# wl_phy_ana_pg_secure register map
Vendor: Texas Instruments
Peripheral module from a debugger description file (folder CC35X1E).
Registers are 32-bit, access per field, reset 0x0 unless marked. A register's access mark holds for its fields unless they carry their own. Offsets are as the file gives them; lines under a group give offsets from that group; [hi:lo] are bit positions; {n}, {i} and the like mark numbered series; 'fields as' and 'values as' point back to an identical list; <NAME> marks a mode.

## wl_phy_ana_pg_secure (part 1 of 3)
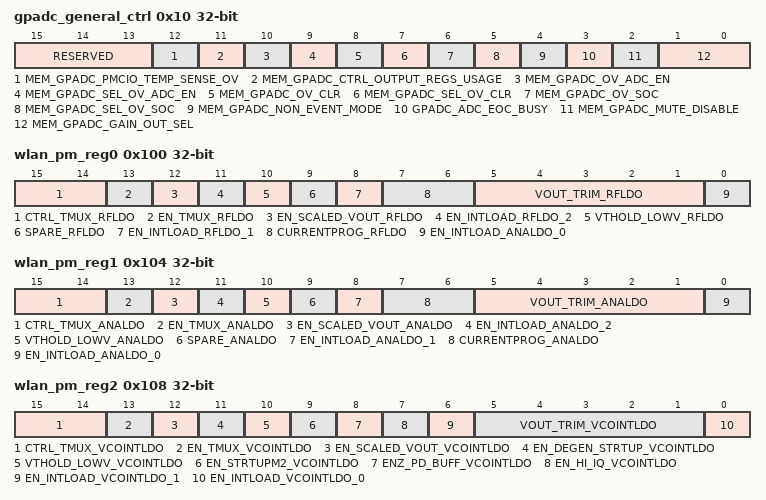
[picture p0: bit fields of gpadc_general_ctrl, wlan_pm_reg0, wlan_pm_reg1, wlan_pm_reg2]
0x10 gpadc_general_ctrl
  [15:13] RESERVED rw, [12] MEM_GPADC_PMCIO_TEMP_SENSE_OV rw, [11] MEM_GPADC_CTRL_OUTPUT_REGS_USAGE rw, [10] MEM_GPADC_OV_ADC_EN rw, [9] MEM_GPADC_SEL_OV_ADC_EN rw, [8] MEM_GPADC_OV_CLR rw, [7] MEM_GPADC_SEL_OV_CLR rw, [6] MEM_GPADC_OV_SOC rw, [5] MEM_GPADC_SEL_OV_SOC rw, [4] MEM_GPADC_NON_EVENT_MODE rw, [3] GPADC_ADC_EOC_BUSY rw, [2] MEM_GPADC_MUTE_DISABLE rw, [1:0] MEM_GPADC_GAIN_OUT_SEL rw
0x70 pmcio_regs
  [15:0] MEM_GPADC_REG0 rw
0x100 wlan_pm_reg0 — Trim bit to control internal load current (EN_INTLOAD)
  [15:14] CTRL_TMUX_RFLDO rw — CTRL_TMUX_1P8V 0_0 _ Bring out VDDA through TMUX 0_1 _ Bring out 2*Iref through TMUX 1_0_ Bring out Vout through TMUX 1_1_ Bring out VSSA through TMUX
  [13] EN_TMUX_RFLDO rw — Enable TMUX _H_ = Enable TMUX block_ _L_ = Disable
  [12] EN_SCALED_VOUT_RFLDO rw — Bring out scaled Vout (Vout_2) _H_ = Enable Vout scale block_ _L_ = Disable
  [11] EN_INTLOAD_RFLDO_2 rw — Trim bit to control internal load current (EN_INTLOAD)
  [10] VTHOLD_LOWV_RFLDO rw — VTHOLD bit of RFLDO30MA_2
  [9] SPARE_RFLDO rw — Spare bit
  [8] EN_INTLOAD_RFLDO_1 rw — Trim bit to control internal load current (EN_INTLOAD)
  [7:6] CURRENTPROG_RFLDO rw — CURRENTPROG Enable extra 80uA current in buffer (CURRENTPROG) Enable extra 40uA current in buffer (CURRENTPROG)
  [5:1] VOUT_TRIM_RFLDO rw — LDO output voltage trim_ VOUT_TRIM LSB = 20mV. For 1.3V output_ trim = 19
  [0] EN_INTLOAD_ANALDO_0 rw — Trim bit to control internal load current (EN_INTLOAD)
0x104 wlan_pm_reg1 — Trim bit to control internal load current (EN_INTLOAD)
  [15:14] CTRL_TMUX_ANALDO rw — CTRL_TMUX_1P8V 0_0 _ Bring out VDDA through TMUX 0_1 _ Bring out 2*Iref through TMUX 1_0_ Bring out Vout through TMUX 1_1_ Bring out VSSA through TMUX
  [13] EN_TMUX_ANALDO rw — Enable TMUX _H_ = Enable TMUX block_ _L_ = Disable
  [12] EN_SCALED_VOUT_ANALDO rw — Bring out scaled Vout (Vout_2) _H_ = Enable Vout scale block_ _L_ = Disable
  [11] EN_INTLOAD_ANALDO_2 rw — Trim bit to control internal load current (EN_INTLOAD)
  [10] VTHOLD_LOWV_ANALDO rw — VTHOLD bit of RFLDO30MA_1
  [9] SPARE_ANALDO rw — Spare bit
  [8] EN_INTLOAD_ANALDO_1 rw — Trim bit to control internal load current (EN_INTLOAD)
  [7:6] CURRENTPROG_ANALDO rw — CURRENTPROG Enable extra 80uA current in buffer (CURRENTPROG) Enable extra 40uA current in buffer (CURRENTPROG)
  [5:1] VOUT_TRIM_ANALDO rw — LDO output voltage trim_ VOUT_TRIM LSB = 20mV. For 1.3V output_ trim = 19
  [0] EN_INTLOAD_ANALDO_0 rw — Trim bit to control internal load current (EN_INTLOAD)
0x108 wlan_pm_reg2 — Trim bit to control internal load current (EN_INTLOAD)
  [15:14] CTRL_TMUX_VCOINTLDO rw — CTRL_TMUX_1P8V 0_0 _ Bring out VDDA through TMUX 0_1 _ Bring out 2*Iref through TMUX 1_0_ Bring out Vout through TMUX 1_1_ Bring out VSSA through TMUX
  [13] EN_TMUX_VCOINTLDO rw — Enable TMUX _H_ = Enable TMUX block_ _L_ = Disable
  [12] EN_SCALED_VOUT_VCOINTLDO rw — Bring out scaled Vout (Vout_2) _H_ = Enable Vout scale block_ _L_ = Disable
  [11] EN_DEGEN_STRTUP_VCOINTLDO rw — Start-up amp's degeneration _L_ = short out degen_ _H_ = keep degen
  [10] VTHOLD_LOWV_VCOINTLDO rw — VTHOLD_LOWV of VCOINTLDO
  [9] EN_STRTUPM2_VCOINTLDO rw — Burn extra current in EA for faster start-up _L_ = only 2.5uA extra_ _H_ = 10uA extra
  [8] ENZ_PD_BUFF_VCOINTLDO rw — Enable PMOS pull down path in buffer _L_ = Enable PD_ _H_ = Disable PD
  [7] EN_HI_IQ_VCOINTLDO rw — Enable high quiescent current mode
  [6] EN_INTLOAD_VCOINTLDO_1 rw — Trim bit to control internal load current (EN_INTLOAD)
  [5:1] VOUT_TRIM_VCOINTLDO rw — LDO output voltage trim_ VOUT_TRIM LSB = 20mV. For 1.3V output_ trim = 19
  [0] EN_INTLOAD_VCOINTLDO_0 rw — Trim bit to control internal load current (EN_INTLOAD)
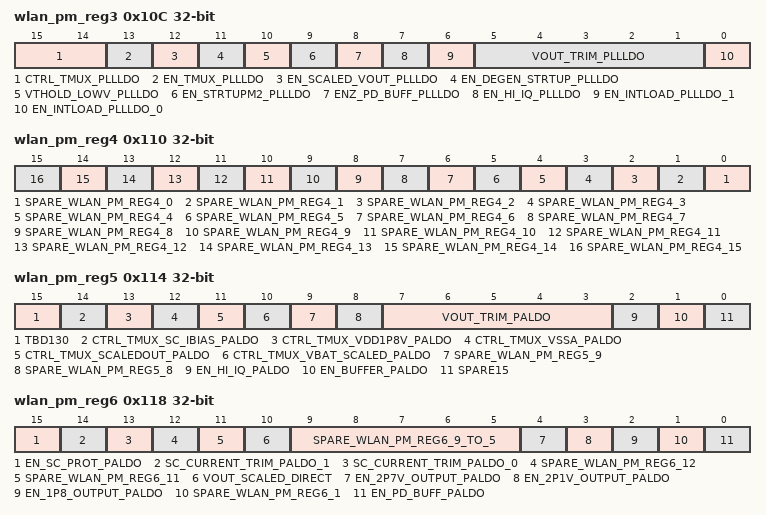
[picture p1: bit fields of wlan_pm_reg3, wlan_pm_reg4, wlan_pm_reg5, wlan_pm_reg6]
0x10C wlan_pm_reg3 — Trim bit to control internal load current (EN_INTLOAD)
  [15:14] CTRL_TMUX_PLLLDO rw — CTRL_TMUX_1P8V 0_0 _ Bring out VDDA through TMUX 0_1 _ Bring out 2*Iref through TMUX 1_0_ Bring out Vout through TMUX 1_1_ Bring out VSSA through TMUX
  [13] EN_TMUX_PLLLDO rw — Enable TMUX _H_ = Enable TMUX block_ _L_ = Disable
  [12] EN_SCALED_VOUT_PLLLDO rw — Bring out scaled Vout (Vout_2) _H_ = Enable Vout scale block_ _L_ = Disable
  [11] EN_DEGEN_STRTUP_PLLLDO rw — Start-up amp's degeneration _L_ = short out degen_ _H_ = keep degen
  [10] VTHOLD_LOWV_PLLLDO rw — VTHOLD_LOWV of PLLLDO
  [9] EN_STRTUPM2_PLLLDO rw — Burn extra current in EA for faster start-up _L_ = only 2.5uA extra_ _H_ = 10uA extra (EN_STARTUPMODE_2)
  [8] ENZ_PD_BUFF_PLLLDO rw — Enable PMOS pull down path in buffer _L_ = Enable PD_ _H_ = Disable PD
  [7] EN_HI_IQ_PLLLDO rw — Enable high quiescent current mode
  [6] EN_INTLOAD_PLLLDO_1 rw — Trim bit to control internal load current (EN_INTLOAD)
  [5:1] VOUT_TRIM_PLLLDO rw — LDO output voltage trim_ VOUT_TRIM LSB = 20mV. For 1.3V output_ trim = 19
  [0] EN_INTLOAD_PLLLDO_0 rw — Trim bit to control internal load current (EN_INTLOAD)
0x110 wlan_pm_reg4 — Spare bit
  [n] SPARE_WLAN_PM_REG4_{n} rw (n=0..15) — Spare bit
0x114 wlan_pm_reg5 — SPARE bit
  [15] TBD130 rw — Unused
  [14] CTRL_TMUX_SC_IBIAS_PALDO rw — Bring out _SC_BIAS_CURRENT_ This will be used for current trimming
  [13] CTRL_TMUX_VDD1P8V_PALDO rw — Bring out _VDD_1P8V_
  [12] CTRL_TMUX_VSSA_PALDO rw — Bring out _VSSA_
  [11] CTRL_TMUX_SCALEDOUT_PALDO rw — Bring out _OUT_SCALED_1P2V_
  [10] CTRL_TMUX_VBAT_SCALED_PALDO rw — Bring out VBAT_SCALED through test-mux Scaling factor = (approx) 0.175 SPARE_REG2 also need to be set to _H_H_ _L_ = Disable_ _H_ = Enable this path in TMUX
  [9] SPARE_WLAN_PM_REG5_9 rw — Spare bit
  [8] SPARE_WLAN_PM_REG5_8 rw — Spare bit
  [7:3] VOUT_TRIM_PALDO rw — LDO output voltage trim_ VOUT_TRIM Bit VOUT_TRIM is unused
  [2] EN_HI_IQ_PALDO rw — Enable high quiescent current mode (HI_IQ_EN) _L_ = Low quiescent current_ _H_ = High quiescent current
  [1] EN_BUFFER_PALDO rw — Enable Buffer (fast loop) of LDO (EN_VBAT_SUPPLY_LOWV) _L_ = Disable_ _H_ = Enable
  [0] SPARE15 rw — SPARE bit
0x118 wlan_pm_reg6 — Enable buffer pull down path (ACTIVE_NMOS_PD_EN) _L_ = Enable pull down_ _H_ = Disable pull down
  [15] EN_SC_PROT_PALDO rw — Enable SC_PROT block _L_ = Disable SC_PROT_ _H_ = Enable SC_PROT
  [14] SC_CURRENT_TRIM_PALDO_1 rw — Unused
  [13] SC_CURRENT_TRIM_PALDO_0 rw — Change the bias current of SC_PROT block _L_ = 5uA current_ _H_ = 10uA current
  [12] SPARE_WLAN_PM_REG6_12 rw — SPARE bit
  [11] SPARE_WLAN_PM_REG6_11 rw — SPARE bit
  [10] VOUT_SCALED_DIRECT rw — Bring out VOUT_SCALED directly through OUT_1P2V pin [Scaling factor (approx.) = 2_9 ] _L_ = Disable_ _H_ = Enable the path to bring out the above mentioned signal (internally called TEST_EN)
  [9:5] SPARE_WLAN_PM_REG6_9_TO_5 rw — SPARE bit
  [4] EN_2P7V_OUTPUT_PALDO rw — Enable High output voltage mode(2.49 - 2.95V) [EN_HIPWR_MODE] _L_ = Operate 2.4V max output_ _H_ = operate at 2.7V max output
  [3] EN_2P1V_OUTPUT_PALDO rw — Enable 1.93V to 2.31V output mode (EN_1P8_SUPPLY_LOWV) H = operate in 1.93V-2.31V output range_ L = operate at higher output Also see SPARE_REG2
  [2] EN_1P8_OUTPUT_PALDO rw — Enable lowest trim range (1.65V - 1.95V) _L_ = Don't enable lowest output mode_ _H_ = Enable lowest trim range_ and override the other two bits
  [1] SPARE_WLAN_PM_REG6_1 rw — SPARE bit
  [0] EN_PD_BUFF_PALDO rw — Enable buffer pull down path (ACTIVE_NMOS_PD_EN) _L_ = Enable pull down_ _H_ = Disable pull down
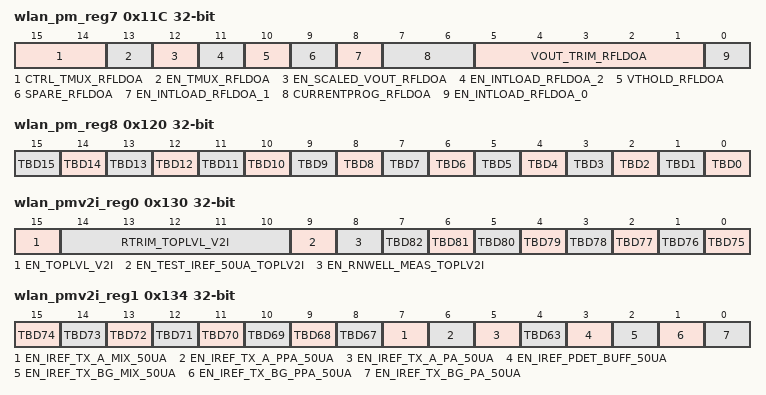
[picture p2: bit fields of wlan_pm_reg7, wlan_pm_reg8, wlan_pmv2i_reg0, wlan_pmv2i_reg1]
0x11C wlan_pm_reg7 — Trim bit to control internal load current (EN_INTLOAD)
  [15:14] CTRL_TMUX_RFLDOA rw — CTRL_TMUX_1P8V 0_0 _ Bring out VDDA through TMUX 0_1 _ Bring out 2*Iref through TMUX 1_0_ Bring out Vout through TMUX 1_1_ Bring out VSSA through TMUX
  [13] EN_TMUX_RFLDOA rw — Enable TMUX _H_ = Enable TMUX block_ _L_ = Disable
  [12] EN_SCALED_VOUT_RFLDOA rw — Bring out scaled Vout (Vout_2) _H_ = Enable Vout scale block_ _L_ = Disable
  [11] EN_INTLOAD_RFLDOA_2 rw — Trim bit to control internal load current (EN_INTLOAD)
  [10] VTHOLD_RFLDOA rw — VTHOLD_LOWV bit for RFLDO60MA
  [9] SPARE_RFLDOA rw — Spare bit
  [8] EN_INTLOAD_RFLDOA_1 rw — Trim bit to control internal load current (EN_INTLOAD)
  [7:6] CURRENTPROG_RFLDOA rw — CURRENTPROG Enable extra 80uA current in buffer (CURRENTPROG) Enable extra 40uA current in buffer (CURRENTPROG)
  [5:1] VOUT_TRIM_RFLDOA rw — LDO output voltage trim_ VOUT_TRIM LSB = 20mV. For 1.3V output_ trim = 19
  [0] EN_INTLOAD_RFLDOA_0 rw — Trim bit to control internal load current (EN_INTLOAD)
0x120 wlan_pm_reg8
  [n] TBD{n} rw (n=0..15)
0x124 wlan_pm_reg9 reset 0x1B001B — MEM_WLAN_PM_REG9
  [15:0] WLAN_PM_REG9_15_0 rw
0x130 wlan_pmv2i_reg0
  [15] EN_TOPLVL_V2I rw — Global enable of V2I _L_ = Disable_ _H_ = Enable V2I module
  [14:10] RTRIM_TOPLVL_V2I rw — RTRIM Nom_27 = 0_1_1_1_1 (15) Nom_-40 = 0_1_1_1_1 (15) Nom_125 = 0_1_0_1_0 (10) Strong_27 = 1_1_1_0_1 (29) Strong_-40 = 1_1_1_1_0 (30) Strong_125 = 1_1_0_1_1 (27) Weak_27 = 0_0_1_0_1 (5) Weak_-40 = 0_0_1_0_1 (5) Weak_125 = 0_0_0_0_0 (0)
  [9] EN_TEST_IREF_50UA_TOPLV2I rw — EN_TEST_IREF_50UA _L_ = Disable_ _H_ = Bring out 50uA test current
  [8] EN_RNWELL_MEAS_TOPLV2I rw — Enable 9.70kOhm resistor for RNWELL measurement
  [n-75] TBD{n} rw (n=75..82)
0x134 wlan_pmv2i_reg1 — IREF_PA_50UA
  [n-59] TBD{n} rw (n=68..74)
  [8] TBD67 rw — TBD (A-band)
  [7] EN_IREF_TX_A_MIX_50UA rw — IREF_MIX_50UA (A)
  [6] EN_IREF_TX_A_PPA_50UA rw — IREF_PPA_50UA (A)
  [5] EN_IREF_TX_A_PA_50UA rw — IREF_PA_50UA (A)
  [4] TBD63 rw
  [3] EN_IREF_PDET_BUFF_50UA rw — PDET_BUF (IREF_50UA)
  [2] EN_IREF_TX_BG_MIX_50UA rw — IREF_MIX_50UA
  [1] EN_IREF_TX_BG_PPA_50UA rw — IREF_PPA_50UA
  [0] EN_IREF_TX_BG_PA_50UA rw — IREF_PA_50UA
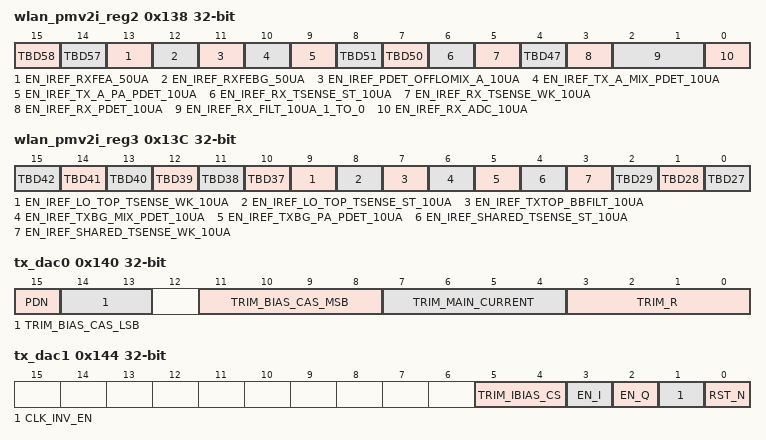
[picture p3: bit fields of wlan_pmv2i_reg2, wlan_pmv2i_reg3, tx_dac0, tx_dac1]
0x138 wlan_pmv2i_reg2 — IREF_ADC_10UA (WLAN_RX_TOP)
  [15] TBD58 rw
  [14] TBD57 rw
  [13] EN_IREF_RXFEA_50UA rw — IREF_ARX_50UA
  [12] EN_IREF_RXFEBG_50UA rw — IREF_RXBG_50UA
  [11] EN_IREF_PDET_OFFLOMIX_A_10UA rw — IREF_PDET_10UA (WLAN_LO_TOP_A)
  [10] EN_IREF_TX_A_MIX_PDET_10UA rw — IREF_MIX_PDET_10UA (A)
  [9] EN_IREF_TX_A_PA_PDET_10UA rw — IREF_PA_PDET_10UA (A)
  [8] TBD51 rw
  [7] TBD50 rw
  [6] EN_IREF_RX_TSENSE_ST_10UA rw — TSENSE_STR_10UA Used for Tsense elements inside WLAN_RX_TOP
  [5] EN_IREF_RX_TSENSE_WK_10UA rw — IREF_TSENSE_WK_10UA Used for Tsense elements inside WLAN_RX_TOP
  [4] TBD47 rw
  [3] EN_IREF_RX_PDET_10UA rw — IREF_PDET_10UA (WLAN_RX_TOP)
  [2:1] EN_IREF_RX_FILT_10UA_1_TO_0 rw — IREF_FILT_20UA (WLAN_RX_TOP)
  [0] EN_IREF_RX_ADC_10UA rw — IREF_ADC_10UA (WLAN_RX_TOP)
0x13C wlan_pmv2i_reg3
  [n-27] TBD{n} rw (n=37..42)
  [9] EN_IREF_LO_TOP_TSENSE_WK_10UA rw — TSENSE_WK_10UA Used for Tsense elements inside WLAN_LO_TOP_AND_TREE (BG)
  [8] EN_IREF_LO_TOP_TSENSE_ST_10UA rw — TSENSE_STR_10UA Used for Tsense elements inside WLAN_LO_TOP_AND_TREE (BG)
  [7] EN_IREF_TXTOP_BBFILT_10UA rw — Iref of biasgen module in TX_BBFILT
  [6] EN_IREF_TXBG_MIX_PDET_10UA rw
  [5] EN_IREF_TXBG_PA_PDET_10UA rw
  [4] EN_IREF_SHARED_TSENSE_ST_10UA rw — TSENSE_WK_10UA Used for Tsense elements of PALDO_ WLAN_TX_TOP (BG _ A)
  [3] EN_IREF_SHARED_TSENSE_WK_10UA rw — TSENSE_STR_10UA Used for Tsense elements of PALDO_ WLAN_TX_TOP (BG _ A)
  [2] TBD29 rw
  [1] TBD28 rw
  [0] TBD27 rw
0x140 tx_dac0 — Trim bits for V2I Resistor
  [15] PDN rw — Enable for the Bias block 0 - Bias Disabled 1 - Bias Enabled
  [14:13] TRIM_BIAS_CAS_LSB rw — Trim bits for Cascode Bias for LSB
  [11:8] TRIM_BIAS_CAS_MSB rw — Trim bits for Cascode Bias for MSB
  [7:4] TRIM_MAIN_CURRENT rw — Trim bits for V2I Current 0000 - 36uA 0001 - 38uA 0011 - 40uA (default) 0111 - 42uA 1111 - 44uA
  [3:0] TRIM_R rw — Trim bits for V2I Resistor
0x144 tx_dac1 — Active Low Reset for DTC
  [5:4] TRIM_IBIAS_CS rw — Trim bits for CS Bias 00 - 500uA DAC Current 01 - 667uA DAC Current (default) 11 - 1mA DAC Current
  [3] EN_I rw — Enable I channel
  [2] EN_Q rw — Enable Q channel
  [1] CLK_INV_EN rw — Invert Clock coming out of DTC
  [0] RST_N rw — Active Low Reset for DTC
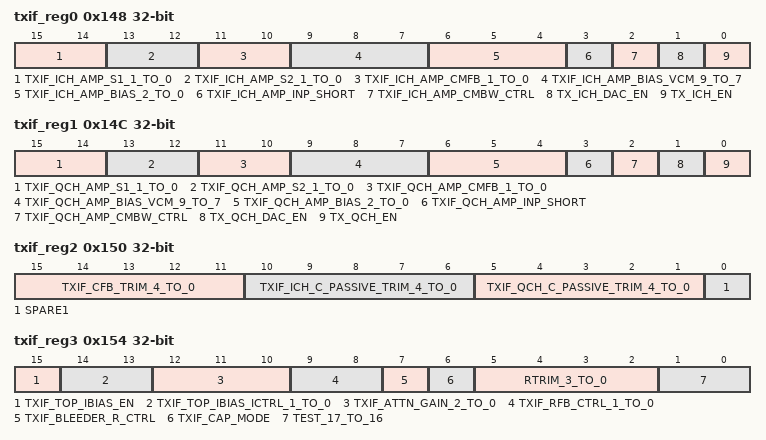
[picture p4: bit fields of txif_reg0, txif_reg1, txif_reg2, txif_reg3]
0x148 txif_reg0 — Enable I Channel Filter
  [15:14] TXIF_ICH_AMP_S1_1_TO_0 rw — Enable S1 Branches of AMP 00 =Disable 10_01 = One Branch 11 = Both Branch
  [13:12] TXIF_ICH_AMP_S2_1_TO_0 rw — Enable S2 Branches of AMP 00 =Disable 10_01 = One Branch 11 = Both Branch
  [11:10] TXIF_ICH_AMP_CMFB_1_TO_0 rw — Enable Branches of CMFB AMP 00 =Disable 10_01 = One Branch 11 = Both Branch
  [9:7] TXIF_ICH_AMP_BIAS_VCM_9_TO_7 rw — Select VCM from Ladder 001=216mV 010=252mV 100=289mV
  [6:4] TXIF_ICH_AMP_BIAS_2_TO_0 rw — AMP Bias control 000=72% (8_11) 001=80% (8_10) 010=89%(8_9) 011=100% (nom)(8_8) 100=114% (8_7) 101=133% (8_6) 110=160% (8_5) 111=200% (8_4)
  [3] TXIF_ICH_AMP_INP_SHORT rw — Short Amp input For Debug
  [2] TXIF_ICH_AMP_CMBW_CTRL rw — Commom mode amp BW control
  [1] TX_ICH_DAC_EN rw — Offset correction DAC enable
  [0] TX_ICH_EN rw — Enable I Channel Filter
0x14C txif_reg1 — Enable Q Channel Filter
  [15:14] TXIF_QCH_AMP_S1_1_TO_0 rw — Enable S1 Branches of AMP 00 =Disable 10_01 = One Branch 11 = Both Branch
  [13:12] TXIF_QCH_AMP_S2_1_TO_0 rw — Enable S2 Branches of AMP 00 =Disable 10_01 = One Branch 11 = Both Branch
  [11:10] TXIF_QCH_AMP_CMFB_1_TO_0 rw — Enable Branches of CMFB AMP 00 =Disable 10_01 = One Branch 11 = Both Branch
  [9:7] TXIF_QCH_AMP_BIAS_VCM_9_TO_7 rw — Select VCM from Ladder 001=216mV 010=252mV 100=289mV
  [6:4] TXIF_QCH_AMP_BIAS_2_TO_0 rw — AMP Bias control 000=72% (8_11) 001=80% (8_10) 010=89%(8_9) 011=100% (nom)(8_8) 100=114% (8_7) 101=133% (8_6) 110=160% (8_5) 111=200% (8_4)
  [3] TXIF_QCH_AMP_INP_SHORT rw — Short Amp input For Debug
  [2] TXIF_QCH_AMP_CMBW_CTRL rw — Commom mode amp BW control
  [1] TX_QCH_DAC_EN rw — Offset correction DAC enable
  [0] TX_QCH_EN rw — Enable Q Channel Filter
0x150 txif_reg2 — SPARE
  [15:11] TXIF_CFB_TRIM_4_TO_0 rw — Both Channel Feedback Cap trim (Active pole) 00000=Min Cap (MAX BW) 01000=Nom Cap(Pole @40MHz) 11111-Max Cap (Min BW)
  [10:6] TXIF_ICH_C_PASSIVE_TRIM_4_TO_0 rw — I Channel Passive Pole Cap trim 00000=Min Cap (MAX BW) 01000=Nom Cap(Pole @60MHz) 11111-Max Cap (Min BW)
  [5:1] TXIF_QCH_C_PASSIVE_TRIM_4_TO_0 rw — Q Channel Passive Pole Cap trim 00000=Min Cap (MAX BW) 01000=Nom Cap(Pole @60MHz) 11111-Max Cap (Min BW)
  [0] SPARE1 rw — SPARE
0x154 txif_reg3 — 000=Disable ICH FILT o_p 110= ICH FILT o_p to TEST 101= ICH FILT o_p to LOOPBACK 011= ICH FILT o_p to Res -LOOPBACK
  [15] TXIF_TOP_IBIAS_EN rw — Top bias Enable
  [14:13] TXIF_TOP_IBIAS_ICTRL_1_TO_0 rw — Top Bias control 11=(8_10) 10=(8_8) 01=(8_6) 00=(8_4)
  [12:10] TXIF_ATTN_GAIN_2_TO_0 rw — Both channel Passive attenuation 000=-12dB 001=-9dB 010=-6dB 011=-3dB 1xx=0dB
  [9:8] TXIF_RFB_CTRL_1_TO_0 rw — Both Channel Feedback R Control 00=800 ohms 01=1200 ohms 10=1600 ohms
  [7] TXIF_BLEEDER_R_CTRL rw — Both channel Bleeder control 0= High R 1= LOW R
  [6] TXIF_CAP_MODE rw — C FB mode 0= LOW BW (HIGH CAP) 1= HIGH BW (LOW CAP)
  [5:2] RTRIM_3_TO_0 rw — Parallel Rtrim 0000= Max R (Strong Corner) 0100= NOM R 1111=MIN R (WEAK corner)
  [1:0] TEST_17_TO_16 rw — 000=Disable ICH FILT o_p 110= ICH FILT o_p to TEST 101= ICH FILT o_p to LOOPBACK 011= ICH FILT o_p to Res -LOOPBACK
0x158 txv2i_reg0 — Spare bits
  [14:0] NOT_USED16 rw
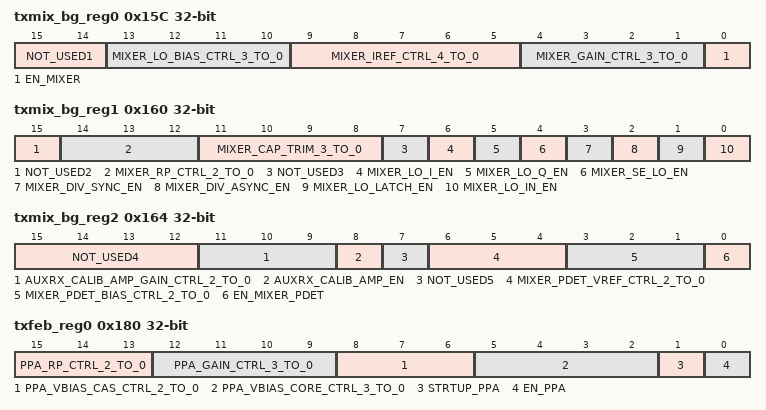
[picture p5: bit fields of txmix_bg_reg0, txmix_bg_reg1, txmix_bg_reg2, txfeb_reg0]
0x15C txmix_bg_reg0 — Enable the Mixer
  [15:14] NOT_USED1 rw — Spare bits
  [13:10] MIXER_LO_BIAS_CTRL_3_TO_0 rw — Control the Mixer LO switch gate bias voltage 0000 - 450mV 0111 - 800mV (default) 1111 - 1.2V
  [9:5] MIXER_IREF_CTRL_4_TO_0 rw — Control the current biasing the Mixer diode_ in steps of 15uA 00000 - 120uA 00001 - 135uA 01000 - 240uA (default) 01111 - 355uA Enabling the MSB doubles the bias current 10000 - 240uA 11111 - 710uA Mixer current is arms*(4_9)*ref
  [4:1] MIXER_GAIN_CTRL_3_TO_0 rw — Control the Mixer gain through gain segments 0000 - 0_30 arms enabled 0110 - 12_30 arms enabled (default) 1111 - 30_30 arms enabled
  [0] EN_MIXER rw — Enable the Mixer
0x160 txmix_bg_reg1 — Enable input buffer for 3.2GHz LO to Mixer
  [15] NOT_USED2 rw — Spare bit
  [14:12] MIXER_RP_CTRL_2_TO_0 rw — Control the parallel resistor at Mixer output_ higher code - lower Mixer gain
  [11:8] MIXER_CAP_TRIM_3_TO_0 rw — Trim bits for the Mixer Output Cap_ in steps of 30f (differential cap value)
  [7] NOT_USED3 rw — Spare bit
  [6] MIXER_LO_I_EN rw — Enable I channel LO of Mixer
  [5] MIXER_LO_Q_EN rw — Enable Q channel LO of Mixer
  [4] MIXER_SE_LO_EN rw — Control bit for Single Ended LO mode of Mixer 0 - Differential LO mode 1 - Single Ended LO mode
  [3] MIXER_DIV_SYNC_EN rw — Enable Synchronous startup mode of Mixer LO Gen
  [2] MIXER_DIV_ASYNC_EN rw — Enable Asynchronous startup mode of Mixer LO Gen
  [1] MIXER_LO_LATCH_EN rw — Enable Mixer LO Gen Latch
  [0] MIXER_LO_IN_EN rw — Enable input buffer for 3.2GHz LO to Mixer
0x164 txmix_bg_reg2 — Enable Mixer PDet
  [15:12] NOT_USED4 rw — Spare bits
  [11:9] AUXRX_CALIB_AMP_GAIN_CTRL_2_TO_0 rw — Control the AuxRx Calib Amp current in steps of 2.8mA (at Nom_27C) 001 - 2.8mA 100 - 11.2mA (default) 111 - 19.6mA
  [8] AUXRX_CALIB_AMP_EN rw — Enable AuxRx IQMM Calibration Amp
  [7] NOT_USED5 rw — Spare bit
  [6:4] MIXER_PDET_VREF_CTRL_2_TO_0 rw — Control the Mixer PDet reference voltage by changing the bias diode current_ in steps of 5uA 000 - 10uA 010 - 20uA (default) 111 - 45uA
  [3:1] MIXER_PDET_BIAS_CTRL_2_TO_0 rw — Control the Mixer PDet bias current_ in steps of 5uA 000 - 10uA 010 - 20uA (default) 111 - 45uA
  [0] EN_MIXER_PDET rw — Enable Mixer PDet
0x168 txmix_bg_reg3 — Spare bits
  [15:0] NOT_USED6 rw
0x16C txmix_bg_reg4 — Spare bits
  [15:0] NOT_USED7 rw
0x170 txdll_reg0 reset 0x1D001D — MEM_TXDLL_REG0
  [15:0] TXDLL_REG0_15_0 rw
0x174 txdll_reg1 reset 0x1E001E — MEM_TXDLL_REG1
  [15:0] TXDLL_REG1_15_0 rw
0x178 txdll_reg2 reset 0x1F001F — MEM_TXDLL_REG2
  [15:0] TXDLL_REG2_15_0 rw
0x17C txdll_reg3 reset 0x200020 — MEM_TXDLL_REG3
  [15:0] TXDLL_REG3_15_0 rw
0x180 txfeb_reg0 — Enable the PPA
  [15:13] PPA_RP_CTRL_2_TO_0 rw — Control the parallel resistor at PPA output_ higher code - lower PPA gain
  [12:9] PPA_GAIN_CTRL_3_TO_0 rw — Control the PPA gain through gain segments_ in steps of 1.6mA 0000 - 0 (PPA disabled) 1000 - 12.8mA (default) 1111 - 24mA
  [8:6] PPA_VBIAS_CAS_CTRL_2_TO_0 rw — Control the PPA cascode bias voltage in steps of 52mV (assuming supply is 1.3V) 000 - 0.88V 011 - 1.04V (default) 111 - 1.25V
  [5:2] PPA_VBIAS_CORE_CTRL_3_TO_0 rw — Control the PPA core bias voltage by changing the bias diode currrent_ in steps of 80uA 0000 - 480uA 0110 - 960uA (default) 1111 - 1.680mA
  [1] STRTUP_PPA rw — Start-up control for the PPA
  [0] EN_PPA rw — Enable the PPA
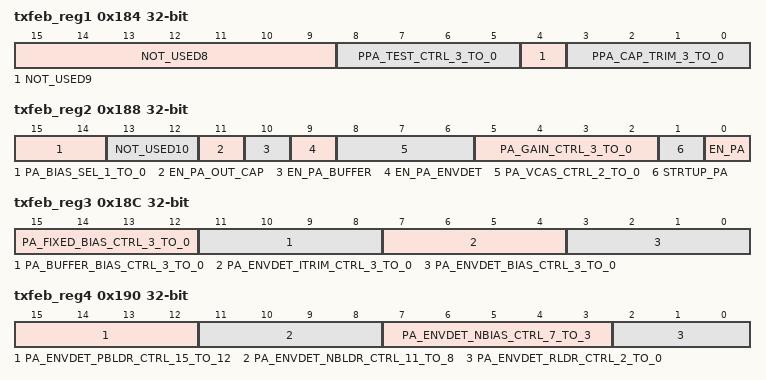
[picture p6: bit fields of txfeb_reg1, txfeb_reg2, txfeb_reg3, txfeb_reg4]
0x184 txfeb_reg1 — Trim bits for the PPA Output Cap_ in steps of 100fF (differential cap value)
  [15:9] NOT_USED8 rw — Spare bits
  [8:5] PPA_TEST_CTRL_3_TO_0 rw — PPA test control bits - PPA_Vbias_Core - PPA_Vbias_Cas - PPA_Itest_20uA - Not used
  [4] NOT_USED9 rw — Spare bits
  [3:0] PPA_CAP_TRIM_3_TO_0 rw — Trim bits for the PPA Output Cap_ in steps of 100fF (differential cap value)
0x188 txfeb_reg2 — Enable the PA
  [15:14] PA_BIAS_SEL_1_TO_0 rw — Select bit for the PA biasing scheme 00 - No bias (PA disabled) 01 - Dynamic bias 10 - Fixed bias
  [13:12] NOT_USED10 rw — Spare bits
  [11] EN_PA_OUT_CAP rw — Enable PA Output Cap
  [10] EN_PA_BUFFER rw — Enable PA Bias Buffer
  [9] EN_PA_ENVDET rw — Enable PA EnvDet
  [8:6] PA_VCAS_CTRL_2_TO_0 rw — Control bits for the PA cascode voltage (assuming supply is 2.70V) 000 - 2.22V 001 - 2.29V 010 - 2.34V 011 - 2.39V 100 - 2.45V 101 - 2.50V (default) 110 - 2.55V 111 - 2.60V
  [5:2] PA_GAIN_CTRL_3_TO_0 rw — Control the PA gain through gain segments
  [1] STRTUP_PA rw — Start-up control for the PA
  [0] EN_PA rw — Enable the PA
0x18C txfeb_reg3 — Control the PA EnvDet bias_ in steps of 10uA 0000 - 40uA 0110 - 100uA (default) 1111 - 190uA
  [15:12] PA_FIXED_BIAS_CTRL_3_TO_0 rw — Control the PA bias in fixed bias mode by changing the bias current_ in steps of 0.2mA 0000 - 1.0mA 0101 - 2.0mA (default) 1111 - 4.0mA
  [11:8] PA_BUFFER_BIAS_CTRL_3_TO_0 rw — Control the PA Buffer bias_ in steps of 10uA 0000 - 40uA 0110 - 100uA (default) 1111 - 190uA
  [7:4] PA_ENVDET_ITRIM_CTRL_3_TO_0 rw — Control the PA EnvDet reference voltage by changing the bias diode current_ in steps of 10uA 0000 - 40uA 0110 - 100uA (default) 1111 - 190uA
  [3:0] PA_ENVDET_BIAS_CTRL_3_TO_0 rw — Control the PA EnvDet bias_ in steps of 10uA 0000 - 40uA 0110 - 100uA (default) 1111 - 190uA
0x190 txfeb_reg4 — Control the PA EnvDet refernce voltage through resistor ladder_ in steps of 52mV (assuming supply is 1.3V) 000 - 0.88V 100 - 1.09V (default) 111 - 1.25V
  [15:12] PA_ENVDET_PBLDR_CTRL_15_TO_12 rw — Control the PA EnvDet pmos bleeder current of the PA_EnvDet_ in steps of 12.5uA 0000 - 0 (default) 1111 - 187.5uA Each code decreases PA gate bias by 6.25mV
  [11:8] PA_ENVDET_NBLDR_CTRL_11_TO_8 rw — Control the PA EnvDet nmos bleeder current of the PA_EnvDet_ in steps of 12.5uA 0000 - 0 (default) 1111 - 187.5uA Each code increases PA gate bias by 6.25mV
  [7:3] PA_ENVDET_NBIAS_CTRL_7_TO_3 rw — Control the PA EnvDet bias current_ in steps of 12.5uA 00000 - 0 10000 - 200uA (default) 11111 - 387.5uA
  [2:0] PA_ENVDET_RLDR_CTRL_2_TO_0 rw — Control the PA EnvDet refernce voltage through resistor ladder_ in steps of 52mV (assuming supply is 1.3V) 000 - 0.88V 100 - 1.09V (default) 111 - 1.25V
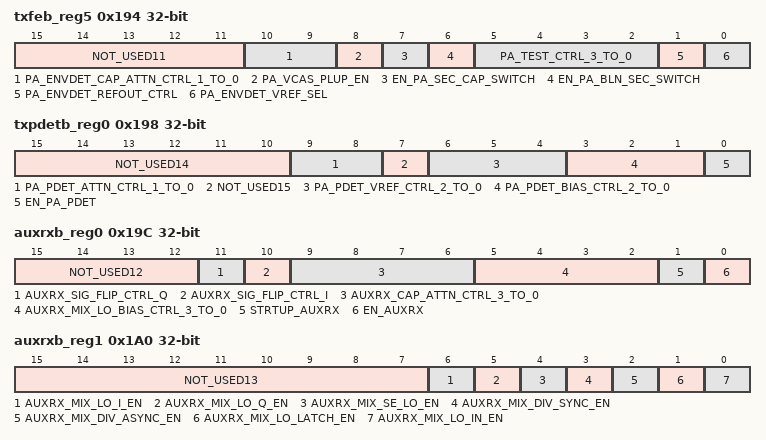
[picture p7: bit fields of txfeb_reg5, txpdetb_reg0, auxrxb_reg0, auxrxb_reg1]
0x194 txfeb_reg5 — Select the PA EnvDet biasing scheme 0 - Diode bias 1 - Resistor ladder bias
  [15:11] NOT_USED11 rw — Spare bits
  [10:9] PA_ENVDET_CAP_ATTN_CTRL_1_TO_0 rw — Control the cap attenuator at the PA EnvDet RF input 00 - 7dB 01 - 10dB 10 - 12dB 11 - 14dB (default)
  [8] PA_VCAS_PLUP_EN rw — Pull up the PA cascode voltage to the PA supply
  [7] EN_PA_SEC_CAP_SWITCH rw — Enable PA secondary cap switch
  [6] EN_PA_BLN_SEC_SWITCH rw — Enable PA balun secondary switch
  [5:2] PA_TEST_CTRL_3_TO_0 rw — PA test control bits - PA_EnvDet_Vout_Vref (PPA PDet) - PA_EnvDet_Vbias - PA_Itest_20uA - PA_Vbias (Fixed Bias mode)
  [1] PA_ENVDET_REFOUT_CTRL rw — Enable PA EnvDet replica bias (enabled when sensing PPA output amplitude)
  [0] PA_ENVDET_VREF_SEL rw — Select the PA EnvDet biasing scheme 0 - Diode bias 1 - Resistor ladder bias
0x198 txpdetb_reg0 — Enable PA PDet
  [15:10] NOT_USED14 rw — Spare bits
  [9:8] PA_PDET_ATTN_CTRL_1_TO_0 rw — Control bits for PA PDet Attenuation 00 - 7.0dB 01 - 10.0dB 10 - 13.5dB 11 - 15.0dB
  [7] NOT_USED15 rw — Spare bit
  [6:4] PA_PDET_VREF_CTRL_2_TO_0 rw — Control the PA PDet reference voltage by changing the bias diode current_ in steps of 5uA 000 - 10uA 010 - 20uA (default) 111 - 45uA
  [3:1] PA_PDET_BIAS_CTRL_2_TO_0 rw — Control the PA PDet bias current_ in steps of 5uA 000 - 10uA 010 - 20uA (default) 111 - 45uA
  [0] EN_PA_PDET rw — Enable PA PDet
0x19C auxrxb_reg0 — Enable the AuxRx
  [15:12] NOT_USED12 rw — Spare bits
  [11] AUXRX_SIG_FLIP_CTRL_Q rw — Flip the signal into AuxRx Q Mixer by 180deg
  [10] AUXRX_SIG_FLIP_CTRL_I rw — Flip the signal into AuxRx I Mixer by 180deg
  [9:6] AUXRX_CAP_ATTN_CTRL_3_TO_0 rw — Control bits for the AuxRx Cap Attenuator
  [5:2] AUXRX_MIX_LO_BIAS_CTRL_3_TO_0 rw — Control the AuxRx Mixer LO switch gate bias voltage in steps of 54mV (assuming supply is 1.3V) 0000 - 0.38V 1001 - 0.86V (default) 1111 - 1.19V
  [1] STRTUP_AUXRX rw — Start-up control for the AuxRx
  [0] EN_AUXRX rw — Enable the AuxRx
0x1A0 auxrxb_reg1 — Enable input buffer for 3.2GHz LO to AuxRx Mixer
  [15:7] NOT_USED13 rw — Spare bits
  [6] AUXRX_MIX_LO_I_EN rw — Enable I channel LO of AuxRx Mixer
  [5] AUXRX_MIX_LO_Q_EN rw — Enable Q channel LO of AuxRx Mixer
  [4] AUXRX_MIX_SE_LO_EN rw — Control bit for Single Ended LO mode of AuxRx Mixer 0 - Differential LO mode 1 - Single Ended LO mode
  [3] AUXRX_MIX_DIV_SYNC_EN rw — Enable Synchronous startup mode of AuxRx Mixer LO Gen
  [2] AUXRX_MIX_DIV_ASYNC_EN rw — Enable Asynchronous startup mode of AuxRx Mixer LO Gen
  [1] AUXRX_MIX_LO_LATCH_EN rw — Enable AuxRx Mixer LO Gen Latch
  [0] AUXRX_MIX_LO_IN_EN rw — Enable input buffer for 3.2GHz LO to AuxRx Mixer
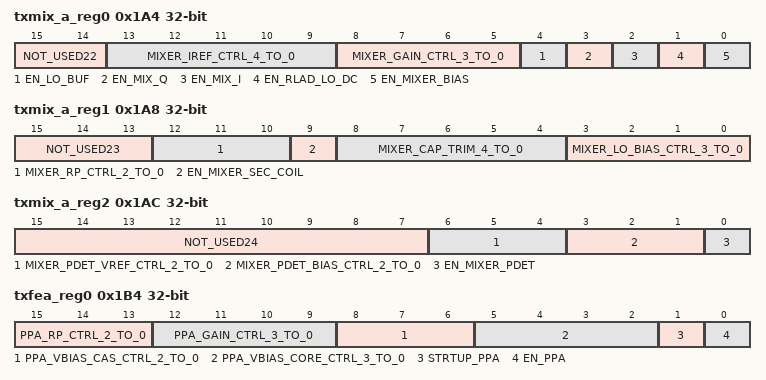
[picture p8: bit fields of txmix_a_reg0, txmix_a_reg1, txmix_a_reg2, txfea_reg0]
0x1A4 txmix_a_reg0 — Enable Mixer Bias
  [15:14] NOT_USED22 rw — Spare bits
  [13:9] MIXER_IREF_CTRL_4_TO_0 rw — Control the current biasing the Mixer diode
  [8:5] MIXER_GAIN_CTRL_3_TO_0 rw — Control the Mixer gain through the gain segments
  [4] EN_LO_BUF rw — Enable LO Buffers
  [3] EN_MIX_Q rw — Enable the Q channel Mixer
  [2] EN_MIX_I rw — Enable the I channel Mixer
  [1] EN_RLAD_LO_DC rw — Enable Resistor Ladder to bias the Mixer LO DC
  [0] EN_MIXER_BIAS rw — Enable Mixer Bias
0x1A8 txmix_a_reg1 — Control bits for the Mixer LO DC bias
  [15:13] NOT_USED23 rw — Spare bits
  [12:10] MIXER_RP_CTRL_2_TO_0 rw — Control the parallel resistor at Mixer output_ higher code - lower Mixer gain
  [9] EN_MIXER_SEC_COIL rw — Enable Mixer Inductor secondary coil (for channel frequencies 6.5GHz)
  [8:4] MIXER_CAP_TRIM_4_TO_0 rw — Trim bits for the Mixer Output Cap
  [3:0] MIXER_LO_BIAS_CTRL_3_TO_0 rw — Control bits for the Mixer LO DC bias
0x1AC txmix_a_reg2 — Enable Mixer PDet
  [15:7] NOT_USED24 rw — Spare bits
  [6:4] MIXER_PDET_VREF_CTRL_2_TO_0 rw — Control the Mixer PDet reference voltage by changing the bias diode current_ in steps of 5uA 000 - 10uA 010 - 20uA (default) 111 - 45uA
  [3:1] MIXER_PDET_BIAS_CTRL_2_TO_0 rw — Control the Mixer PDet bias current_ in steps of 5uA 000 - 10uA 010 - 20uA (default) 111 - 45uA
  [0] EN_MIXER_PDET rw — Enable Mixer PDet
0x1B0 txmix_a_reg3 — Spare bits
  [15:0] NOT_USED25 rw
0x1B4 txfea_reg0 — Enable the PPA
  [15:13] PPA_RP_CTRL_2_TO_0 rw — Control the parallel resistor at PPA output_ higher code - lower PPA gain
  [12:9] PPA_GAIN_CTRL_3_TO_0 rw — Control the PPA gain through gain segments_ in steps of 1.6mA 0000 - 0 (PPA disabled) 1000 - 12.8m (default) 1111 - 24mA
  [8:6] PPA_VBIAS_CAS_CTRL_2_TO_0 rw — Control the PPA cascode bias voltage in steps of 52mV (assuming supply is 1.3V) 000 - 0.88V 011 - 1.04V (default) 111 - 1.25V
  [5:2] PPA_VBIAS_CORE_CTRL_3_TO_0 rw — Control the PPA core bias voltage by changing the bias diode currrent_ in steps of 80uA 0000 - 480uA 0101 - 960uA (default) 1111 - 1.680mA
  [1] STRTUP_PPA rw — Start-up control for the PPA
  [0] EN_PPA rw — Enable the PPA
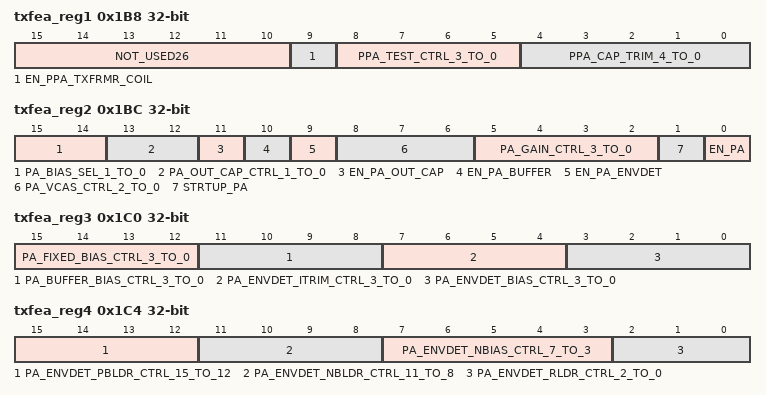
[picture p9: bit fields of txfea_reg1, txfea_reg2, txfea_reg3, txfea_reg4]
0x1B8 txfea_reg1 — Trim bits for the PPA Output Cap_ in steps of 50fF (differential cap value)
  [15:10] NOT_USED26 rw — Spare bits
  [9] EN_PPA_TXFRMR_COIL rw — Enable PPA Transformer tertiary coil (for channel frequencies 6.5GHz)
  [8:5] PPA_TEST_CTRL_3_TO_0 rw — PPA test control bits - PPA_Vbias_Core - PPA_Vbias_Cas - PPA_Itest_20uA - Not used
  [4:0] PPA_CAP_TRIM_4_TO_0 rw — Trim bits for the PPA Output Cap_ in steps of 50fF (differential cap value)
0x1BC txfea_reg2 — Enable the PA
  [15:14] PA_BIAS_SEL_1_TO_0 rw — Select bit for the PA biasing scheme 00 - No bias (PA disabled) 01 - Dynamic bias 10 - Fixed bias
  [13:12] PA_OUT_CAP_CTRL_1_TO_0 rw — Control bits for the PA Output Cap (differential cap values provided here) 00 - no cap engaged 01 - 0.25pF 10 - 0.50pF 11 - 0.75pF
  [11] EN_PA_OUT_CAP rw — Enable PA Output Cap
  [10] EN_PA_BUFFER rw — Enable PA Bias Buffer
  [9] EN_PA_ENVDET rw — Enable PA EnvDet
  [8:6] PA_VCAS_CTRL_2_TO_0 rw — Control bits for the PA cascode voltage (assuming supply is 2.70V) 000 - 2.22V 001 - 2.29V 010 - 2.34V 011 - 2.39V 100 - 2.45V 101 - 2.50V (default) 110 - 2.55V 111 - 2.60V
  [5:2] PA_GAIN_CTRL_3_TO_0 rw — Control the PA gain through gain segments
  [1] STRTUP_PA rw — Start-up control for the PA
  [0] EN_PA rw — Enable the PA
0x1C0 txfea_reg3 — Control the PA EnvDet bias_ in steps of 10uA 0000 - 40uA 0110 - 100uA (default) 1111 - 190uA
  fields as txfeb_reg3
0x1C4 txfea_reg4 — Control the PA EnvDet reference voltage through resistor ladder_ in steps of 52mV (assuming supply is 1.3V) 000 - 0.88V 100 - 1.09V (default) 111 - 1.25V
  [15:12] PA_ENVDET_PBLDR_CTRL_15_TO_12 rw — Control the PA EnvDet pmos bleeder current of the PA_EnvDet_ in steps of 12.5uA 0000 - 0 (default) 1111 - 187.5uA Each code decreases PA gate bias by 6.25mV
  [11:8] PA_ENVDET_NBLDR_CTRL_11_TO_8 rw — Control the PA EnvDet nmos bleeder current of the PA_EnvDet_ in steps of 12.5uA 0000 - 0 (default) 1111 - 187.5uA Each code increases PA gate bias by 6.25mV
  [7:3] PA_ENVDET_NBIAS_CTRL_7_TO_3 rw — Control the PA EnvDet bias current_ in steps of 12.5uA 00000 - 0 10000 - 200uA (default) 11111 - 387.5uA
  [2:0] PA_ENVDET_RLDR_CTRL_2_TO_0 rw — Control the PA EnvDet reference voltage through resistor ladder_ in steps of 52mV (assuming supply is 1.3V) 000 - 0.88V 100 - 1.09V (default) 111 - 1.25V
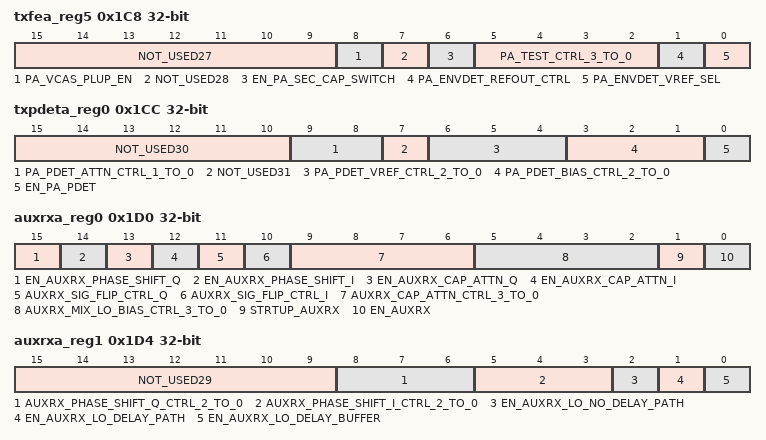
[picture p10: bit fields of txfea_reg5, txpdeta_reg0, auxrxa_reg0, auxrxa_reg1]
0x1C8 txfea_reg5 — Select the PA EnvDet biasing scheme 0 - Diode bias 1 - Resistor ladder bias
  [15:9] NOT_USED27 rw — Spare bits
  [8] PA_VCAS_PLUP_EN rw — Pull up the PA cascode voltage to the PA supply
  [7] NOT_USED28 rw — Spare bit
  [6] EN_PA_SEC_CAP_SWITCH rw — Enable PA secondary cap switch
  [5:2] PA_TEST_CTRL_3_TO_0 rw — PA test control bits - PA_EnvDet_Vout_Vref (PPA PDet) - PA_EnvDet_Vbias - PA_Itest_20uA - PA_Vbias (Fixed Bias mode)
  [1] PA_ENVDET_REFOUT_CTRL rw — Enable PA EnvDet replica bias (enabled when sensing PPA output amplitude)
  [0] PA_ENVDET_VREF_SEL rw — Select the PA EnvDet biasing scheme 0 - Diode bias 1 - Resistor ladder bias
0x1CC txpdeta_reg0 — Enable PA PDet
  [15:10] NOT_USED30 rw — Spare bits
  [9:8] PA_PDET_ATTN_CTRL_1_TO_0 rw — Control bits for PA PDet Attenuation 00 - 7.0dB 01 - 10.0dB 10 - 13.5dB 11 - 15.0dB
  [7] NOT_USED31 rw — Spare bit
  [6:4] PA_PDET_VREF_CTRL_2_TO_0 rw — Control the PA PDet reference voltage by changing the bias diode current_ in steps of 5uA 000 - 10uA 010 - 20uA (default) 111 - 45uA
  [3:1] PA_PDET_BIAS_CTRL_2_TO_0 rw — Control the PA PDet bias current_ in steps of 5uA 000 - 10uA 010 - 20uA (default) 111 - 45uA
  [0] EN_PA_PDET rw — Enable PA PDet
0x1D0 auxrxa_reg0 — Enable the AuxRx
  [15] EN_AUXRX_PHASE_SHIFT_Q rw — Enable AuxRx RC Phase Shifter for Q Mixer
  [14] EN_AUXRX_PHASE_SHIFT_I rw — Enable AuxRx RC Phase Shifter for I Mixer
  [13] EN_AUXRX_CAP_ATTN_Q rw — Enable AuxRx Cap Attenuator for Q Mixer
  [12] EN_AUXRX_CAP_ATTN_I rw — Enable AuxRx Cap Attenuator for I Mixer
  [11] AUXRX_SIG_FLIP_CTRL_Q rw — Flip the signal into AuxRx Q Mixer by 180deg
  [10] AUXRX_SIG_FLIP_CTRL_I rw — Flip the signal into AuxRx I Mixer by 180deg
  [9:6] AUXRX_CAP_ATTN_CTRL_3_TO_0 rw — Control bits for the AuxRx Cap Attenuator
  [5:2] AUXRX_MIX_LO_BIAS_CTRL_3_TO_0 rw — Control the AuxRx Mixer LO switch gate bias voltage in steps of 54mV (assuming supply is 1.3V) 0000 - 0.38V 1001 - 0.86V (default) 1111 - 1.19V
  [1] STRTUP_AUXRX rw — Start-up control for the AuxRx
  [0] EN_AUXRX rw — Enable the AuxRx
0x1D4 auxrxa_reg1 — Enable buffers in the LO delay path
  [15:9] NOT_USED29 rw — Spare bits
  [8:6] AUXRX_PHASE_SHIFT_Q_CTRL_2_TO_0 rw — Resistor control bits for the Q channel AuxRx RC Phase Shifter_ higher code - lower resistance
  [5:3] AUXRX_PHASE_SHIFT_I_CTRL_2_TO_0 rw — Resistor control bits for the I channel AuxRx RC Phase Shifter_ higher code - lower resistance
  [2] EN_AUXRX_LO_NO_DELAY_PATH rw — Enable LO no-delay path
  [1] EN_AUXRX_LO_DELAY_PATH rw — Enable LO delay path
  [0] EN_AUXRX_LO_DELAY_BUFFER rw — Enable buffers in the LO delay path
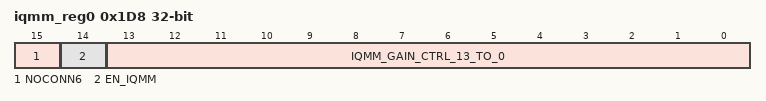
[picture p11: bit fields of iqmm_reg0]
0x1D8 iqmm_reg0 — Gain control bits for IQMM block
  [15] NOCONN6 rw — Not connected
  [14] EN_IQMM rw — Enable bit for IQMM block
  [13:0] IQMM_GAIN_CTRL_13_TO_0 rw — Gain control bits for IQMM block
